# f2837xs_flash_ecc_regs register map
Vendor: Texas Instruments
Peripheral module from a debugger description file (folder C2000).
Address unit: 16 bits
Registers are 32-bit, read-write, no defined reset value unless marked. A register's access mark holds for its fields unless they carry their own. Offsets are as the file gives them; lines under a group give offsets from that group; [hi:lo] are bit positions; {n}, {i} and the like mark numbered series; 'fields as' and 'values as' point back to an identical list; <NAME> marks a mode.

## FLASH_ECC_REGS — FLASH ECC Registers
0x00 ECC_ENABLE
  [3:0] ENABLE — Enable ECC
0x02 SINGLE_ERR_ADDR_LOW — Single Error Address Low
  [31:0] ERR_ADDR_L — Lower 64 bit Single Bit Error Address
0x04 SINGLE_ERR_ADDR_HIGH — Single Error Address High
  [31:0] ERR_ADDR_H — Upper 64 bit Single Bit Error Address
0x06 UNC_ERR_ADDR_LOW — Uncorrectable Error Address Low
  [31:0] UNC_ERR_ADDR_L — Lower 64 bit Uncorrectable Error Address
0x08 UNC_ERR_ADDR_HIGH — Uncorrectable Error Address High
  [31:0] UNC_ERR_ADDR_H — Upper 64 bit Uncorrectable Error Address
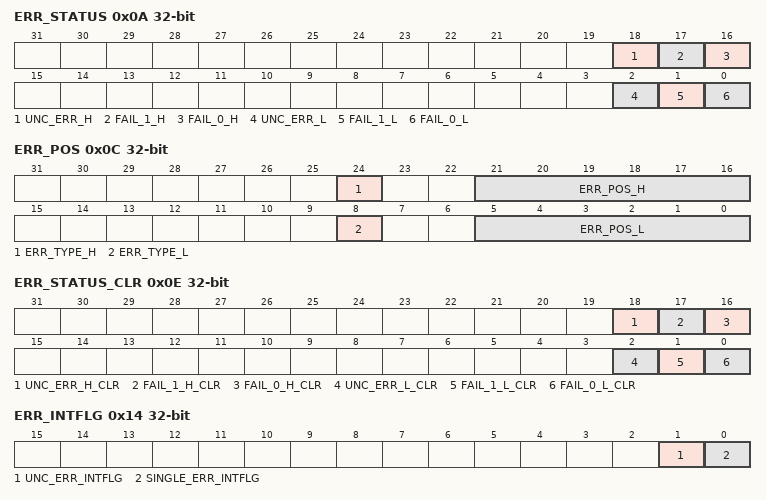
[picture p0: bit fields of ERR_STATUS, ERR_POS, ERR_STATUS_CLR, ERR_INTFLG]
0x0A ERR_STATUS ro — Error Status
  [18] UNC_ERR_H — Upper 64 bits Uncorrectable error occurred
  [17] FAIL_1_H — Upper 64bits Single Bit Error Corrected Value 1
  [16] FAIL_0_H — Upper 64bits Single Bit Error Corrected Value 0
  [2] UNC_ERR_L — Lower 64 bits Uncorrectable error occurred
  [1] FAIL_1_L — Lower 64bits Single Bit Error Corrected Value 1
  [0] FAIL_0_L — Lower 64bits Single Bit Error Corrected Value 0
0x0C ERR_POS ro — Error Position
  [24] ERR_TYPE_H — Error Type in upper 64 bits
  [21:16] ERR_POS_H — Bit Position of Single bit Error in upper 64 bits
  [8] ERR_TYPE_L — Error Type in lower 64 bits
  [5:0] ERR_POS_L — Bit Position of Single bit Error in lower 64 bits
0x0E ERR_STATUS_CLR access not given — Error Status Clear
  [18] UNC_ERR_H_CLR — Upper 64 bits Uncorrectable error occurred Clear (access R=0/W=1)
  [17] FAIL_1_H_CLR — Upper 64bits Single Bit Error Corrected Value 1 Clear (access R=0/W=1)
  [16] FAIL_0_H_CLR — Upper 64bits Single Bit Error Corrected Value 0 Clear (access R=0/W=1)
  [2] UNC_ERR_L_CLR — Lower 64 bits Uncorrectable error occurred Clear (access R=0/W=1)
  [1] FAIL_1_L_CLR — Lower 64bits Single Bit Error Corrected Value 1 Clear (access R=0/W=1)
  [0] FAIL_0_L_CLR — Lower 64bits Single Bit Error Corrected Value 0 Clear (access R=0/W=1)
0x10 ERR_CNT — Error Control
  [15:0] ERR_CNT — Error counter
0x12 ERR_THRESHOLD — Error Threshold
  [15:0] ERR_THRESHOLD
0x14 ERR_INTFLG ro — Error Interrupt Flag
  [1] UNC_ERR_INTFLG — Uncorrectable Interrupt Flag
  [0] SINGLE_ERR_INTFLG — Single Error Interrupt Flag
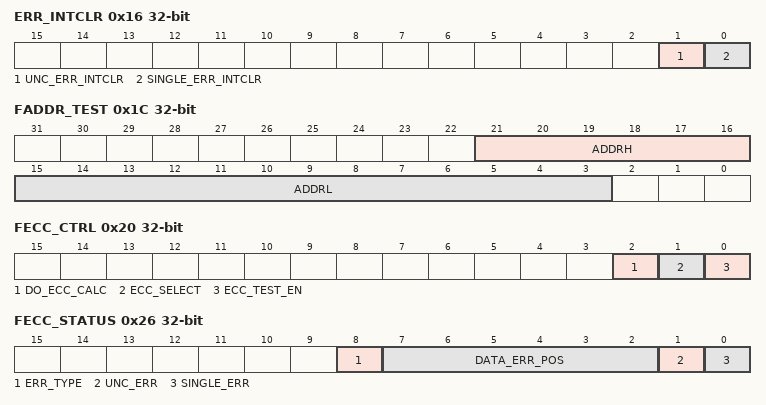
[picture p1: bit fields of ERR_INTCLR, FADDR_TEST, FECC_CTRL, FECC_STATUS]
0x16 ERR_INTCLR access not given — Error Interrupt Flag Clear
  [1] UNC_ERR_INTCLR — Uncorrectable Interrupt Flag Clear (access R=0/W=1)
  [0] SINGLE_ERR_INTCLR — Single Error Interrupt Flag Clear (access R=0/W=1)
0x18 FDATAH_TEST — Data High Test
  [31:0] FDATAH
0x1A FDATAL_TEST — Data Low Test
  [31:0] FDATAL
0x1C FADDR_TEST — ECC Test Address
  [21:16] ADDRH — ECC Address High
  [15:3] ADDRL — ECC Address Low
0x1E FECC_TEST — ECC Test Address
  [7:0] ECC — ECC Control Bits
0x20 FECC_CTRL access not given — ECC Control
  [2] DO_ECC_CALC — Enable ECC Calculation (access R=0/W=1)
  [1] ECC_SELECT rw — ECC Bit Select
  [0] ECC_TEST_EN rw — Enable ECC Test Logic
0x22 FOUTH_TEST ro — Test Data Out High
  [31:0] DATAOUTH
0x24 FOUTL_TEST ro — Test Data Out Low
  [31:0] DATAOUTL
0x26 FECC_STATUS ro — ECC Status
  [8] ERR_TYPE — Holds Bit Position of 8 Check Bits of Error
  [7:2] DATA_ERR_POS — Holds Bit Position of Error
  [1] UNC_ERR — Test Result is Uncorrectable Error
  [0] SINGLE_ERR — Test Result is Single Bit Error
